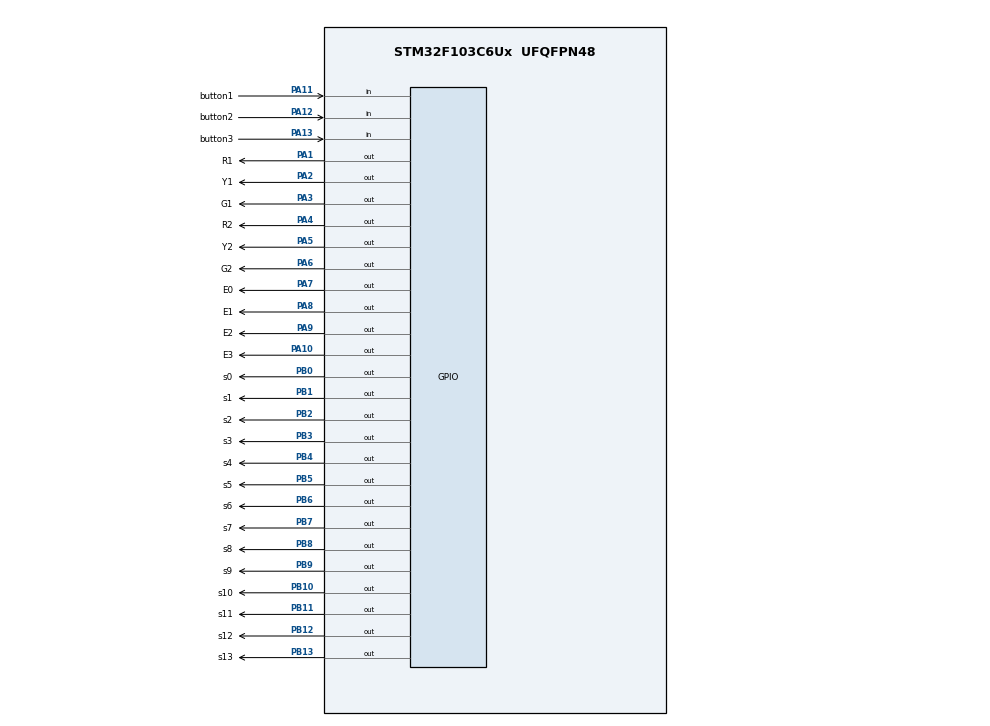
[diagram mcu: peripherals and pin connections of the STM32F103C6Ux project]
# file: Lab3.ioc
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Mcu.Family=STM32F1
Mcu.Name=STM32F103C6Ux
Mcu.Package=UFQFPN48
NVIC.PriorityGroup=NVIC_PRIORITYGROUP_4
NVIC.TIM2_IRQn=true\:0\:0\:false\:false\:true\:true\:true
PA1.GPIO_Label=R1
PA1.Signal=GPIO_Output
PA10.GPIO_Label=E3
PA10.Signal=GPIO_Output
PA11.GPIO_Label=button1
PA11.GPIO_PuPd=GPIO_PULLUP
PA11.Signal=GPIO_Input
PA12.GPIO_Label=button2
PA12.GPIO_PuPd=GPIO_PULLUP
PA12.Signal=GPIO_Input
PA13.GPIO_Label=button3
PA13.GPIO_PuPd=GPIO_PULLUP
PA13.Signal=GPIO_Input
PA2.GPIO_Label=Y1
PA2.Signal=GPIO_Output
PA3.GPIO_Label=G1
PA3.Signal=GPIO_Output
PA4.GPIO_Label=R2
PA4.Signal=GPIO_Output
PA5.GPIO_Label=Y2
PA5.Signal=GPIO_Output
PA6.GPIO_Label=G2
PA6.Signal=GPIO_Output
PA7.GPIO_Label=E0
PA7.Signal=GPIO_Output
PA8.GPIO_Label=E1
PA8.Signal=GPIO_Output
PA9.GPIO_Label=E2
PA9.Signal=GPIO_Output
PB0.GPIO_Label=s0
PB0.Signal=GPIO_Output
PB1.GPIO_Label=s1
PB1.Signal=GPIO_Output
PB10.GPIO_Label=s10
PB10.Signal=GPIO_Output
PB11.GPIO_Label=s11
PB11.Signal=GPIO_Output
PB12.GPIO_Label=s12
PB12.Signal=GPIO_Output
PB13.GPIO_Label=s13
PB13.Signal=GPIO_Output
PB2.GPIO_Label=s2
PB2.Signal=GPIO_Output
PB3.GPIO_Label=s3
PB3.Signal=GPIO_Output
PB4.GPIO_Label=s4
PB4.Signal=GPIO_Output
PB5.GPIO_Label=s5
PB5.Signal=GPIO_Output
PB6.GPIO_Label=s6
PB6.Signal=GPIO_Output
PB7.GPIO_Label=s7
PB7.Signal=GPIO_Output
PB8.GPIO_Label=s8
PB8.Signal=GPIO_Output
PB9.GPIO_Label=s9
PB9.Signal=GPIO_Output
ProjectManager.HeapSize=0x200
ProjectManager.StackSize=0x400
ProjectManager.TargetToolchain=STM32CubeIDE
RCC.APB1Freq_Value=8000000
RCC.APB2Freq_Value=8000000
TIM2.Period=9
TIM2.Prescaler=7999
VP_SYS_VS_ND.Mode=No_Debug
VP_TIM2_VS_ClockSourceINT.Mode=Internal
board=custom

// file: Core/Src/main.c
/* USER CODE BEGIN Header */
/**
  ******************************************************************************
  * @file           : main.c
  * @brief          : Main program body
  ******************************************************************************
  * @attention
  *
  * <h2><center>&copy; Copyright (c) 2024 STMicroelectronics.
  * All rights reserved.</center></h2>
  *
  * This software component is licensed by ST under BSD 3-Clause license,
  * the "License"; You may not use this file except in compliance with the
  * License. You may obtain a copy of the License at:
  *                        opensource.org/licenses/BSD-3-Clause
  *
  ******************************************************************************
  */
/* USER CODE END Header */
#include "main.h"
#include "software_timer.h"
#include "global.h"

/* USER CODE BEGIN PV */
TIM_HandleTypeDef htim2;
/* USER CODE END PV */

void SystemClock_Config(void);
static void MX_GPIO_Init(void);
static void MX_TIM2_Init(void);

void led_red(){
	HAL_GPIO_WritePin(R1_GPIO_Port, R1_Pin, RESET);
}
void led_greeen(){
	HAL_GPIO_WritePin(G1_GPIO_Port, G1_Pin, RESET);
}
void led_yellow(){
	HAL_GPIO_WritePin(Y1_GPIO_Port, Y1_Pin, RESET);
}
int main(void)
{

  /* MCU Configuration--------------------------------------------------------*/

  /* Reset of all peripherals, Initializes the Flash interface and the Systick. */
  HAL_Init();

  /* Configure the system clock */
  SystemClock_Config();

  /* Initialize all configured peripherals */
  MX_GPIO_Init();
  MX_TIM2_Init();
  /* USER CODE BEGIN 2 */
  HAL_TIM_Base_Start_IT(&htim2);
  /* USER CODE END 2 */
  status1=AUTO_GREEN;
  status2=AUTO_RED;
  setTimer1(50);
  setTimer2(50);
  /* Infinite loop */
//  SCH_Add_Task(led_red, 0, 500);
//  SCH_Add_Task(led_greeen, 100, 700);
//  SCH_Add_Task(led_yellow, 200, 200);
  while (1)
  {
	  fsm_manual_run();
//	  SCH_Update();
//	  SCH_Dispatch_Tasks();
  }
}

void SystemClock_Config(void)
{
  RCC_OscInitTypeDef RCC_OscInitStruct = {0};
  RCC_ClkInitTypeDef RCC_ClkInitStruct = {0};

  /** Initializes the RCC Oscillators according to the specified parameters
  * in the RCC_OscInitTypeDef structure.
  */
  RCC_OscInitStruct.OscillatorType = RCC_OSCILLATORTYPE_HSI;
  RCC_OscInitStruct.HSIState = RCC_HSI_ON;
  RCC_OscInitStruct.HSICalibrationValue = RCC_HSICALIBRATION_DEFAULT;
  RCC_OscInitStruct.PLL.PLLState = RCC_PLL_NONE;
  if (HAL_RCC_OscConfig(&RCC_OscInitStruct) != HAL_OK)
  {
    Error_Handler();
  }
  /** Initializes the CPU, AHB and APB buses clocks
  */
  RCC_ClkInitStruct.ClockType = RCC_CLOCKTYPE_HCLK|RCC_CLOCKTYPE_SYSCLK
                              |RCC_CLOCKTYPE_PCLK1|RCC_CLOCKTYPE_PCLK2;
  RCC_ClkInitStruct.SYSCLKSource = RCC_SYSCLKSOURCE_HSI;
  RCC_ClkInitStruct.AHBCLKDivider = RCC_SYSCLK_DIV1;
  RCC_ClkInitStruct.APB1CLKDivider = RCC_HCLK_DIV1;
  RCC_ClkInitStruct.APB2CLKDivider = RCC_HCLK_DIV1;

  if (HAL_RCC_ClockConfig(&RCC_ClkInitStruct, FLASH_LATENCY_0) != HAL_OK)
  {
    Error_Handler();
  }
}

static void MX_TIM2_Init(void)
{

  TIM_ClockConfigTypeDef sClockSourceConfig = {0};
  TIM_MasterConfigTypeDef sMasterConfig = {0};

  htim2.Instance = TIM2;
  htim2.Init.Prescaler = 7999;
  htim2.Init.CounterMode = TIM_COUNTERMODE_UP;
  htim2.Init.Period = 9;
  htim2.Init.ClockDivision = TIM_CLOCKDIVISION_DIV1;
  htim2.Init.AutoReloadPreload = TIM_AUTORELOAD_PRELOAD_DISABLE;
  if (HAL_TIM_Base_Init(&htim2) != HAL_OK)
  {
    Error_Handler();
  }
  sClockSourceConfig.ClockSource = TIM_CLOCKSOURCE_INTERNAL;
  if (HAL_TIM_ConfigClockSource(&htim2, &sClockSourceConfig) != HAL_OK)
  {
    Error_Handler();
  }
  sMasterConfig.MasterOutputTrigger = TIM_TRGO_RESET;
  sMasterConfig.MasterSlaveMode = TIM_MASTERSLAVEMODE_DISABLE;
  if (HAL_TIMEx_MasterConfigSynchronization(&htim2, &sMasterConfig) != HAL_OK)
  {
    Error_Handler();
  }

}

static void MX_GPIO_Init(void)
{
  GPIO_InitTypeDef GPIO_InitStruct = {0};

  /* GPIO Ports Clock Enable */
  __HAL_RCC_GPIOA_CLK_ENABLE();
  __HAL_RCC_GPIOB_CLK_ENABLE();

  /*Configure GPIO pin Output Level */
  HAL_GPIO_WritePin(GPIOA, R1_Pin|Y1_Pin|G1_Pin|R2_Pin
                          |Y2_Pin|G2_Pin|E0_Pin|E1_Pin
                          |E2_Pin|E3_Pin, GPIO_PIN_RESET);

  /*Configure GPIO pin Output Level */
  HAL_GPIO_WritePin(GPIOB, s0_Pin|s1_Pin|s2_Pin|s10_Pin
                          |s11_Pin|s12_Pin|s13_Pin|s3_Pin
                          |s4_Pin|s5_Pin|s6_Pin|s7_Pin
                          |s8_Pin|s9_Pin, GPIO_PIN_RESET);

  /*Configure GPIO pins : R1_Pin Y1_Pin G1_Pin R2_Pin
                           Y2_Pin G2_Pin E0_Pin E1_Pin
                           E2_Pin E3_Pin */
  GPIO_InitStruct.Pin = R1_Pin|Y1_Pin|G1_Pin|R2_Pin
                          |Y2_Pin|G2_Pin|E0_Pin|E1_Pin
                          |E2_Pin|E3_Pin;
  GPIO_InitStruct.Mode = GPIO_MODE_OUTPUT_PP;
  GPIO_InitStruct.Pull = GPIO_NOPULL;
  GPIO_InitStruct.Speed = GPIO_SPEED_FREQ_LOW;
  HAL_GPIO_Init(GPIOA, &GPIO_InitStruct);

  /*Configure GPIO pins : s0_Pin s1_Pin s2_Pin s10_Pin
                           s11_Pin s12_Pin s13_Pin s3_Pin
                           s4_Pin s5_Pin s6_Pin s7_Pin
                           s8_Pin s9_Pin */
  GPIO_InitStruct.Pin = s0_Pin|s1_Pin|s2_Pin|s10_Pin
                          |s11_Pin|s12_Pin|s13_Pin|s3_Pin
                          |s4_Pin|s5_Pin|s6_Pin|s7_Pin
                          |s8_Pin|s9_Pin;
  GPIO_InitStruct.Mode = GPIO_MODE_OUTPUT_PP;
  GPIO_InitStruct.Pull = GPIO_NOPULL;
  GPIO_InitStruct.Speed = GPIO_SPEED_FREQ_LOW;
  HAL_GPIO_Init(GPIOB, &GPIO_InitStruct);

  /*Configure GPIO pins : button1_Pin button2_Pin button3_Pin */
  GPIO_InitStruct.Pin = button1_Pin|button2_Pin|button3_Pin;
  GPIO_InitStruct.Mode = GPIO_MODE_INPUT;
  GPIO_InitStruct.Pull = GPIO_PULLUP;
  HAL_GPIO_Init(GPIOA, &GPIO_InitStruct);

}

/* USER CODE BEGIN 4 */
void HAL_TIM_PeriodElapsedCallback(TIM_HandleTypeDef *htim){
	timer_run();
	getKeyInput();
//	SCH_Update();
}
/* USER CODE END 4 */

void Error_Handler(void)
{
  __disable_irq();
  while (1)
  {
  }
}

/************************ (C) COPYRIGHT STMicroelectronics *****END OF FILE****/
